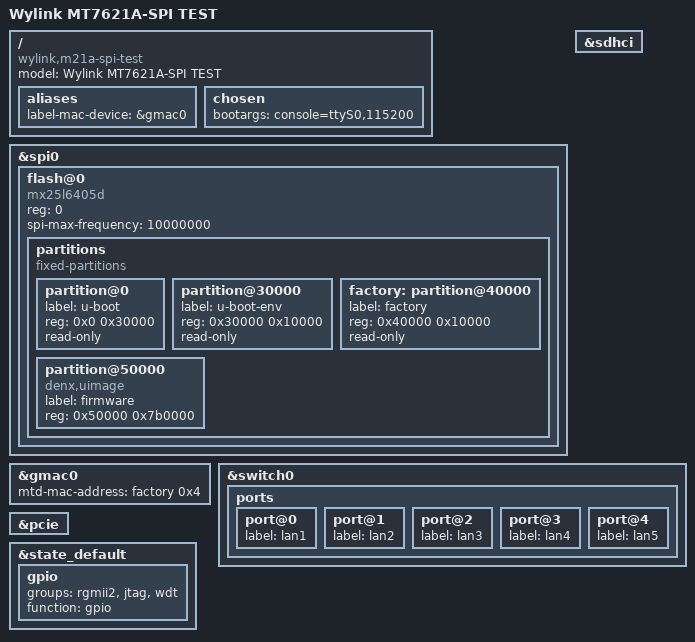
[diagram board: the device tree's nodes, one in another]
#include "mt7621.dtsi"

/ {
	compatible = "wylink,m21a-spi-test", "mediatek,mt7621-soc";
	model = "Wylink MT7621A-SPI TEST";

	aliases {
		label-mac-device = &gmac0;
	};

	chosen {
		bootargs = "console=ttyS0,115200";
	};

};

&spi0 {
	status = "okay";

	flash@0 {
		compatible = "mx25l6405d","jedec,spi-nor";
		reg = <0>;
		spi-max-frequency = <10000000>;

		partitions {
			compatible = "fixed-partitions";
			#address-cells = <1>;
			#size-cells = <1>;

			partition@0 {
				label = "u-boot";
				reg = <0x0 0x30000>;
				read-only;
			};

			partition@30000 {
				label = "u-boot-env";
				reg = <0x30000 0x10000>;
				read-only;
			};

			factory: partition@40000 {
				label = "factory";
				reg = <0x40000 0x10000>;
				read-only;
			};

			partition@50000 {
				compatible = "denx,uimage";
				label = "firmware";
				reg = <0x50000 0x7b0000>;
			};
		};
	};
};

&sdhci {
	status = "okay";
};

&gmac0 {
	mtd-mac-address = <&factory 0x4>;
};

&switch0 {
	ports {
		port@0 {
			status = "okay";
			label = "lan1";
		};

		port@1 {
			status = "okay";
			label = "lan2";
		};

		port@2 {
			status = "okay";
			label = "lan3";
		};

		port@3 {
			status = "okay";
			label = "lan4";
		};

		port@4 {
			status = "okay";
			label = "lan5";
		};
	};
};

&pcie {
	status = "okay";
};

&state_default {
	gpio {
		groups = "rgmii2", "jtag", "wdt";
		function = "gpio";
	};
};
